# BL702 register map
Vendor: Bouffalo Lab; Series: WiFi BT; File version: 1.0
Registers are 32-bit, read-write, reset 0x0 unless marked. A register's access mark holds for its fields unless they carry their own. Offsets are from the block's base; [hi:lo] are bit positions; {n}, {i} and the like mark numbered series.

## kys — Key Scan
Base 0x4000AB00
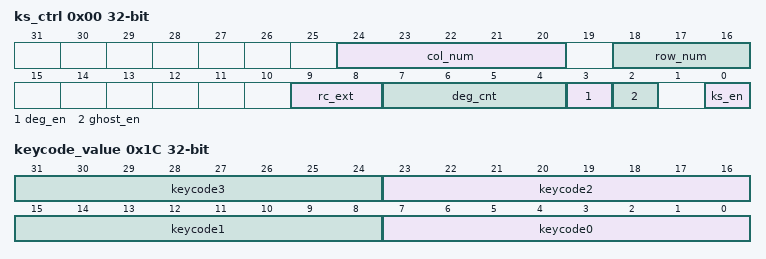
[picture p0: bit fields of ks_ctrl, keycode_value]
0x00 ks_ctrl
  [24:20] col_num, [18:16] row_num, [9:8] rc_ext, [7:4] deg_cnt, [3] deg_en, [2] ghost_en, [0] ks_en
0x10 ks_int_en
  [0] ks_int_en
0x14 ks_int_sts
  [3:0] keycode_valid
0x18 keycode_clr
  [3:0] keycode_clr
0x1C keycode_value
  [8n+7:8n] keycode{n} (n=0..3)

## I2S — Inter-IC Sound controller
Base 0x4000AA00
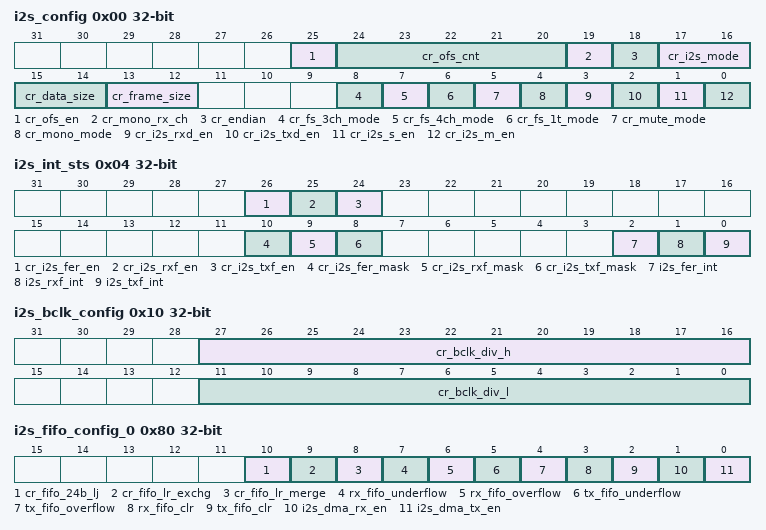
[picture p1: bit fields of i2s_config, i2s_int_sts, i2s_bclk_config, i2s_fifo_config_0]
0x00 i2s_config
  [25] cr_ofs_en, [24:20] cr_ofs_cnt, [19] cr_mono_rx_ch, [18] cr_endian, [17:16] cr_i2s_mode, [15:14] cr_data_size, [13:12] cr_frame_size, [8] cr_fs_3ch_mode, [7] cr_fs_4ch_mode, [6] cr_fs_1t_mode, [5] cr_mute_mode, [4] cr_mono_mode, [3] cr_i2s_rxd_en, [2] cr_i2s_txd_en, [1] cr_i2s_s_en, [0] cr_i2s_m_en
0x04 i2s_int_sts
  [26] cr_i2s_fer_en, [25] cr_i2s_rxf_en, [24] cr_i2s_txf_en, [10] cr_i2s_fer_mask, [9] cr_i2s_rxf_mask, [8] cr_i2s_txf_mask, [2] i2s_fer_int, [1] i2s_rxf_int, [0] i2s_txf_int
0x10 i2s_bclk_config
  [27:16] cr_bclk_div_h, [11:0] cr_bclk_div_l
0x80 i2s_fifo_config_0
  [10] cr_fifo_24b_lj, [9] cr_fifo_lr_exchg, [8] cr_fifo_lr_merge, [7] rx_fifo_underflow, [6] rx_fifo_overflow, [5] tx_fifo_underflow, [4] tx_fifo_overflow, [3] rx_fifo_clr, [2] tx_fifo_clr, [1] i2s_dma_rx_en, [0] i2s_dma_tx_en
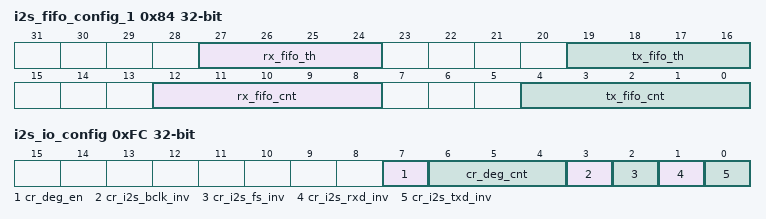
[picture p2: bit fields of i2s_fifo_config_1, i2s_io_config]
0x84 i2s_fifo_config_1
  [27:24] rx_fifo_th, [19:16] tx_fifo_th, [12:8] rx_fifo_cnt, [4:0] tx_fifo_cnt
0x88 i2s_fifo_wdata
0x8C i2s_fifo_rdata
0xFC i2s_io_config
  [7] cr_deg_en, [6:4] cr_deg_cnt, [3] cr_i2s_bclk_inv, [2] cr_i2s_fs_inv, [1] cr_i2s_rxd_inv, [0] cr_i2s_txd_inv

## cam — Camera
Base 0x4000AD00
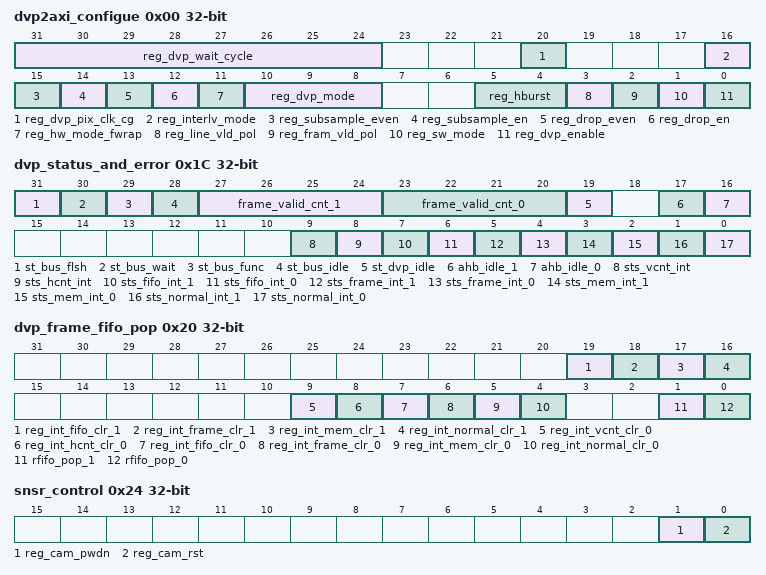
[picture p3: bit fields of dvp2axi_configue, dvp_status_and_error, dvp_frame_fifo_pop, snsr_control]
0x00 dvp2axi_configue
  [31:24] reg_dvp_wait_cycle, [20] reg_dvp_pix_clk_cg, [16] reg_interlv_mode, [15] reg_subsample_even, [14] reg_subsample_en, [13] reg_drop_even, [12] reg_drop_en, [11] reg_hw_mode_fwrap, [10:8] reg_dvp_mode, [5:4] reg_hburst, [3] reg_line_vld_pol, [2] reg_fram_vld_pol, [1] reg_sw_mode, [0] reg_dvp_enable
0x04 dvp2ahb_addr_start_0
  [31:0] reg_addr_start_0
0x08 dvp2ahb_mem_bcnt_0
  [31:0] reg_mem_burst_cnt_0
0x0C dvp2ahb_frame_bcnt_0
  [31:0] reg_frame_burst_cnt_0
0x10 dvp2ahb_addr_start_1
  [31:0] reg_addr_start_1
0x14 dvp2ahb_mem_bcnt_1
  [31:0] reg_mem_burst_cnt_1
0x18 dvp2ahb_frame_bcnt_1
  [31:0] reg_frame_burst_cnt_1
0x1C dvp_status_and_error
  [31] st_bus_flsh, [30] st_bus_wait, [29] st_bus_func, [28] st_bus_idle, [27:24] frame_valid_cnt_1, [23:20] frame_valid_cnt_0, [19] st_dvp_idle, [17] ahb_idle_1, [16] ahb_idle_0, [9] sts_vcnt_int, [8] sts_hcnt_int, [7] sts_fifo_int_1, [6] sts_fifo_int_0, [5] sts_frame_int_1, [4] sts_frame_int_0, [3] sts_mem_int_1, [2] sts_mem_int_0, [1] sts_normal_int_1, [0] sts_normal_int_0
0x20 dvp_frame_fifo_pop
  [19] reg_int_fifo_clr_1, [18] reg_int_frame_clr_1, [17] reg_int_mem_clr_1, [16] reg_int_normal_clr_1, [9] reg_int_vcnt_clr_0, [8] reg_int_hcnt_clr_0, [7] reg_int_fifo_clr_0, [6] reg_int_frame_clr_0, [5] reg_int_mem_clr_0, [4] reg_int_normal_clr_0, [1] rfifo_pop_1, [0] rfifo_pop_0
0x24 snsr_control
  [1] reg_cam_pwdn, [0] reg_cam_rst
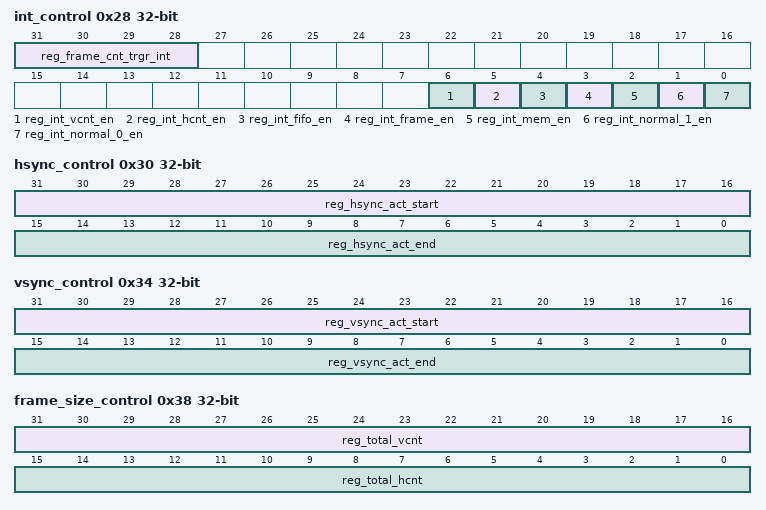
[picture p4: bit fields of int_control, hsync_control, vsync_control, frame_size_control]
0x28 int_control
  [31:28] reg_frame_cnt_trgr_int, [6] reg_int_vcnt_en, [5] reg_int_hcnt_en, [4] reg_int_fifo_en, [3] reg_int_frame_en, [2] reg_int_mem_en, [1] reg_int_normal_1_en, [0] reg_int_normal_0_en
0x30 hsync_control
  [31:16] reg_hsync_act_start, [15:0] reg_hsync_act_end
0x34 vsync_control
  [31:16] reg_vsync_act_start, [15:0] reg_vsync_act_end
0x38 frame_size_control
  [31:16] reg_total_vcnt, [15:0] reg_total_hcnt
{0x40+8i} frame_start_addr0_{i} (i=0..7)
  [31:0] frame_start_addr_0_{i}
{0x44+8i} frame_byte_cnt0_{i} (i=0..7)
  [31:0] frame_byte_cnt_0_{i}
{0x80+8i} frame_start_addr1_{i} (i=0..7)
  [31:0] frame_start_addr_1_{i}
{0x84+8i} frame_byte_cnt1_{i} (i=0..7)
  [31:0] frame_byte_cnt_1_{i}
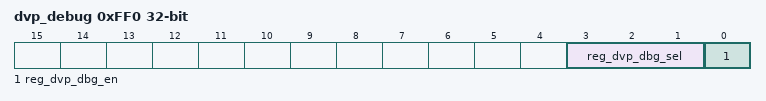
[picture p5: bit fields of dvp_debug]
0xFF0 dvp_debug
  [3:1] reg_dvp_dbg_sel, [0] reg_dvp_dbg_en
0xFFC dvp_dummy_reg
